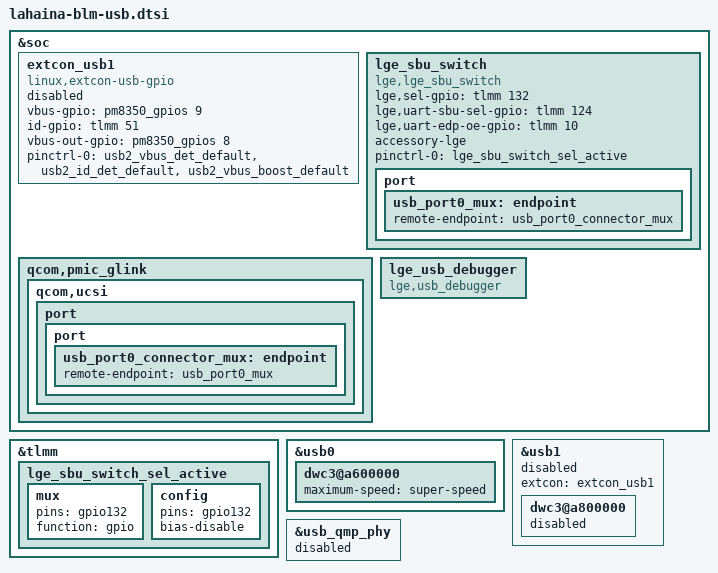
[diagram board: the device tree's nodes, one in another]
#include "../lahaina-blm_common/lahaina-blm_common-usb.dtsi"

&soc {
    extcon_usb1: extcon_usb1 {
        status = "disabled";
        compatible = "linux,extcon-usb-gpio";
        vbus-gpio =  <&pm8350_gpios 9 GPIO_ACTIVE_HIGH>;
        id-gpio = <&tlmm 51 GPIO_ACTIVE_HIGH>;
        vbus-out-gpio = <&pm8350_gpios 8 GPIO_ACTIVE_HIGH>;

        pinctrl-names = "default";
        pinctrl-0 = <&usb2_vbus_det_default
                 &usb2_id_det_default
                 &usb2_vbus_boost_default>;
    };

    lge_sbu_switch: lge_sbu_switch {
        compatible = "lge,lge_sbu_switch";
        lge,sel-gpio = <&tlmm 132 0>;
        lge,uart-sbu-sel-gpio = <&tlmm 124 0>;
        lge,uart-edp-oe-gpio = <&tlmm 10 0>;
        accessory-lge;

        pinctrl-names = "default";
        pinctrl-0 = <&lge_sbu_switch_sel_active>;

        port {
            usb_port0_mux: endpoint {
                remote-endpoint = <&usb_port0_connector_mux>;
            };
        };
    };

    qcom,pmic_glink {
        qcom,ucsi {
            port {
                port {
                    usb_port0_connector_mux: endpoint {
                        remote-endpoint = <&usb_port0_mux>;
                    };
                };
            };
        };
    };

    lge_usb_debugger: lge_usb_debugger {
        compatible = "lge,usb_debugger";
    };
};

&tlmm {
    lge_sbu_switch_sel_active: lge_sbu_switch_sel_active {
        mux {
            pins = "gpio132";
            function = "gpio";
        };

        config {
            pins = "gpio132";
            bias-disable;
        };
    };
};

&usb0 {
    dwc3@a600000 {
        maximum-speed = "super-speed";
    };
};

&usb1 {
    status = "disabled";
    extcon = <&extcon_usb1>;
    dwc3@a800000 {
        status = "disabled";
    };
};

&usb_qmp_phy {
    status = "disabled";
};

